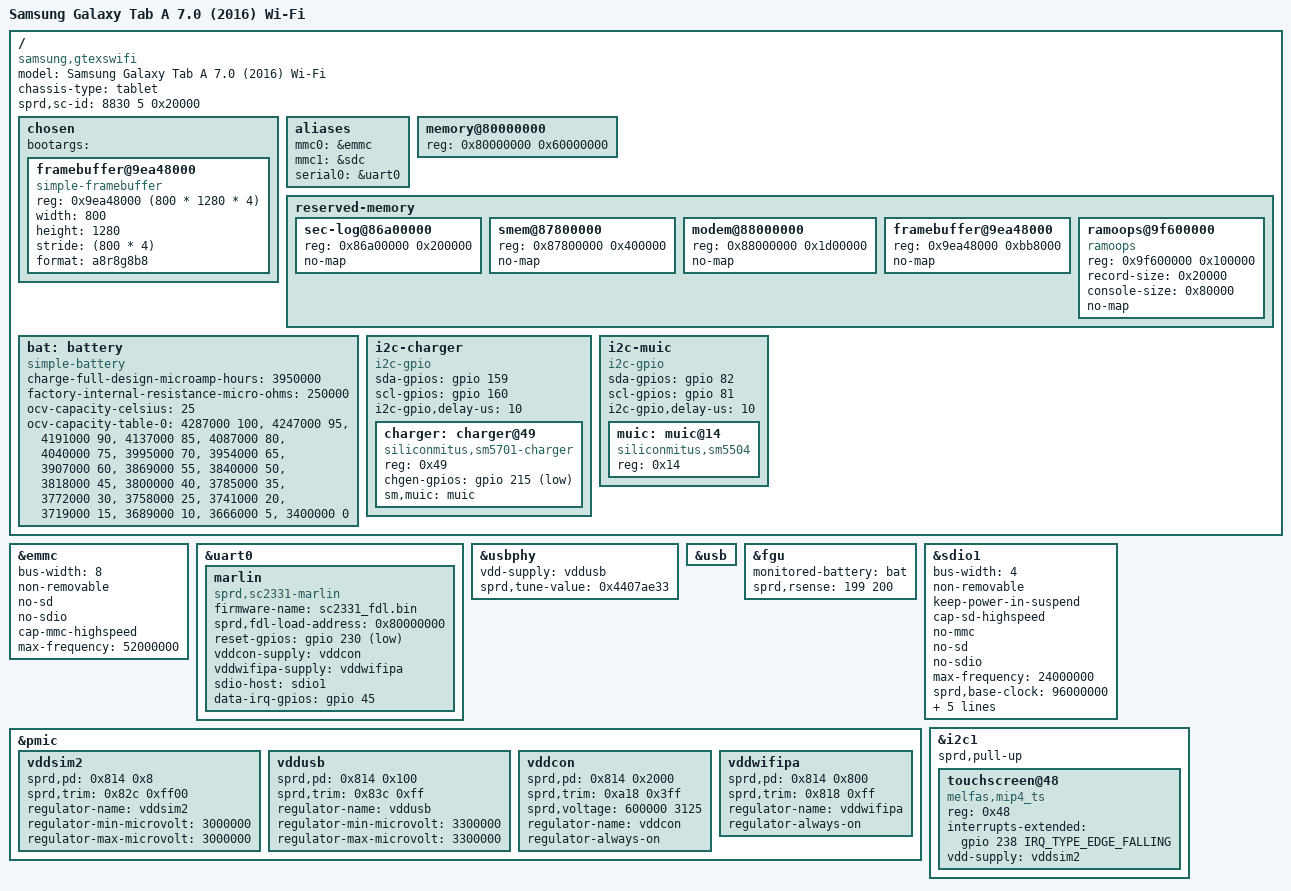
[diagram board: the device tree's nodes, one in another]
// SPDX-License-Identifier: GPL-2.0
/*
 * Samsung Galaxy Tab A 7.0 (2016) Wi-Fi (SM-T280, gtexswifi)
 */

/dts-v1/;

#include <dt-bindings/gpio/gpio.h>
#include "sc7730.dtsi"

/ {
	model = "Samsung Galaxy Tab A 7.0 (2016) Wi-Fi";
	compatible = "samsung,gtexswifi", "sprd,sc7730";
	chassis-type = "tablet";

	/* SBOOT picks the DTB out of dt.img by this id and the board revision */
	sprd,sc-id = <8830 5 0x20000>;

	chosen {
		#address-cells = <1>;
		#size-cells = <1>;
		ranges;

		/* SBOOT writes its own bootargs here; the kernel uses CONFIG_CMDLINE */
		bootargs = "";

		/* SBOOT leaves the panel running and scanning out lcd_base */
		framebuffer@9ea48000 {
			compatible = "simple-framebuffer";
			reg = <0x9ea48000 (800 * 1280 * 4)>;
			width = <800>;
			height = <1280>;
			stride = <(800 * 4)>;
			format = "a8r8g8b8";
		};
	};

	aliases {
		mmc0 = &emmc;
		mmc1 = &sdc;
		serial0 = &uart0;
	};

	memory@80000000 {
		device_type = "memory";
		reg = <0x80000000 0x60000000>;
	};

	reserved-memory {
		#address-cells = <1>;
		#size-cells = <1>;
		ranges;

		/* Samsung sec_debug and sec_log buffers */
		sec-log@86a00000 {
			reg = <0x86a00000 0x200000>;
			no-map;
		};

		/* IPC shared memory and modem images loaded by SBOOT */
		smem@87800000 {
			reg = <0x87800000 0x400000>;
			no-map;
		};

		modem@88000000 {
			reg = <0x88000000 0x1d00000>;
			no-map;
		};

		/* triple-buffered vendor framebuffer, first buffer is lcd_base */
		framebuffer@9ea48000 {
			reg = <0x9ea48000 0xbb8000>;
			no-map;
		};

		/*
		 * Vendor ION carveout. TWRP's kernel never touches it, so a
		 * log left here can be read back from /dev/mem after a reboot.
		 */
		ramoops@9f600000 {
			compatible = "ramoops";
			reg = <0x9f600000 0x100000>;
			record-size = <0x20000>;
			console-size = <0x80000>;
			no-map;
		};
	};
};

&emmc {
	bus-width = <8>;
	non-removable;
	no-sd;
	no-sdio;
	cap-mmc-highspeed;
	max-frequency = <52000000>;
	status = "okay";
};

/*
 * Marlin SC2331 WiFi/BT: load FDL1 over UART0 before probing SDIO1. The
 * loader owns GPIO 230 so it can reproduce the vendor reset pulse.
 */
&uart0 {
	status = "okay";

	marlin {
		compatible = "sprd,sc2331-marlin";
		firmware-name = "sc2331_fdl.bin";
		/* The FDL vectors contain absolute pointers based at this address. */
		sprd,fdl-load-address = <0x80000000>;
		reset-gpios = <&gpio 230 GPIO_ACTIVE_LOW>;
		vddcon-supply = <&vddcon>;
		vddwifipa-supply = <&vddwifipa>;
		sdio-host = <&sdio1>;
		/* vendor sprd-marlin gpios: 0 = wake ack (148), 1 = data irq (45), 2 = wake out (46) */
		data-irq-gpios = <&gpio 45 GPIO_ACTIVE_HIGH>;
	};
};

/* the battery, data from the vendor sprd-scx35_gtexswifi_battery_r00.dtsi */
/ {
	bat: battery {
		compatible = "simple-battery";
		charge-full-design-microamp-hours = <3950000>;
		factory-internal-resistance-micro-ohms = <250000>;
		ocv-capacity-celsius = <25>;
		ocv-capacity-table-0 = <4287000 100>, <4247000 95>, <4191000 90>, <4137000 85>,
				       <4087000 80>, <4040000 75>, <3995000 70>, <3954000 65>,
				       <3907000 60>, <3869000 55>, <3840000 50>, <3818000 45>,
				       <3800000 40>, <3785000 35>, <3772000 30>, <3758000 25>,
				       <3741000 20>, <3719000 15>, <3689000 10>, <3666000 5>,
				       <3400000 0>;
	};
};

&usbphy {
	vdd-supply = <&vddusb>;
	sprd,tune-value = <0x4407ae33>;	/* the board's tune_value */
	status = "okay";
};

&usb {
	status = "okay";
};

/*
 * Charger and MUIC, each on a GPIO I2C bus as in the vendor DTS (i2c_gpio6 and i2c_gpio7):
 * SM5701 charger at 0x49 (SDA GPIO 159, SCL GPIO 160, charge enable GPIO 215 active low),
 * SM5504 MUIC at 0x14 (SDA GPIO 82, SCL GPIO 81)
 */
/ {
	i2c-charger {
		compatible = "i2c-gpio";
		sda-gpios = <&gpio 159 (GPIO_ACTIVE_HIGH | GPIO_OPEN_DRAIN)>;
		scl-gpios = <&gpio 160 (GPIO_ACTIVE_HIGH | GPIO_OPEN_DRAIN)>;
		i2c-gpio,delay-us = <10>;
		#address-cells = <1>;
		#size-cells = <0>;

		charger: charger@49 {
			compatible = "siliconmitus,sm5701-charger";
			reg = <0x49>;
			chgen-gpios = <&gpio 215 GPIO_ACTIVE_LOW>;
			sm,muic = <&muic>;
		};
	};

	i2c-muic {
		compatible = "i2c-gpio";
		sda-gpios = <&gpio 82 (GPIO_ACTIVE_HIGH | GPIO_OPEN_DRAIN)>;
		scl-gpios = <&gpio 81 (GPIO_ACTIVE_HIGH | GPIO_OPEN_DRAIN)>;
		i2c-gpio,delay-us = <10>;
		#address-cells = <1>;
		#size-cells = <0>;

		muic: muic@14 {
			compatible = "siliconmitus,sm5504";
			reg = <0x14>;
		};
	};
};

&fgu {
	monitored-battery = <&bat>;
	sprd,rsense = <199 200>;	/* sense resistor, real and specified (0.1 mOhm) */
	status = "okay";
};

&sdio1 {
	bus-width = <4>;
	non-removable;
	keep-power-in-suspend;
	cap-sd-highspeed;
	no-mmc;
	no-sd;
	/* FDL1 must start the chip before the host sends CMD5. */
	no-sdio;
	max-frequency = <24000000>;
	sprd,base-clock = <96000000>;
	sprd,init-regs = <0x402e3020 0x000f0007 0x00000000>,	/* CLK_AUX0: 32 kHz, no divider */
			 <0x402e0004 0x00000004 0x00000004>,	/* AON APB_EB1: AUX0 on */
			 <0x7120004c 0x00000003 0x00000002>,	/* SDIO1 clock: 96 MHz */
			 <0x20d00000 0x00000200 0x00000200>;	/* AP AHB EB: SDIO1 on */
	status = "okay";
};

&pmic {
	/* touchscreen supply; the vendor touch driver runs it at 3.0 V */
	vddsim2: vddsim2 {
		sprd,pd = <0x814 0x8>;
		sprd,trim = <0x82c 0xff00>;
		regulator-name = "vddsim2";
		regulator-min-microvolt = <3000000>;
		regulator-max-microvolt = <3000000>;
	};

	/* USB PHY, 3.3 V as the vendor's usb_ldo_switch() */
	vddusb: vddusb {
		sprd,pd = <0x814 0x100>;
		sprd,trim = <0x83c 0xff>;
		regulator-name = "vddusb";
		regulator-min-microvolt = <3300000>;
		regulator-max-microvolt = <3300000>;
	};

	/* Marlin: download/core DC-DC, its voltage as the bootloader left it (the vendor asks 1.6 V) */
	vddcon: vddcon {
		sprd,pd = <0x814 0x2000>;
		sprd,trim = <0xa18 0x3ff>;
		sprd,voltage = <600000 3125>;
		regulator-name = "vddcon";
		regulator-always-on;
	};

	/*
	 * Marlin: "vdd-pa", 3.3 V per the vendor DTS comment, 1.8 V per its regulator default; nobody
	 * in the vendor kernel sets it, so leave the voltage alone and only switch it on
	 */
	vddwifipa: vddwifipa {
		sprd,pd = <0x814 0x800>;
		sprd,trim = <0x818 0xff>;
		regulator-name = "vddwifipa";
		regulator-always-on;
	};
};

&i2c1 {
	sprd,pull-up;
	status = "okay";

	touchscreen@48 {
		compatible = "melfas,mip4_ts";
		reg = <0x48>;
		interrupts-extended = <&gpio 238 IRQ_TYPE_EDGE_FALLING>;
		vdd-supply = <&vddsim2>;
	};
};
